# PIC32CM5112GC00048 device description
Architecture: CORTEX-M23; Family: PIC32CM; Series: PIC32CMGC00
Registers are 32-bit, read-write, reset 0x0 unless marked. A register's access mark holds for its fields unless they carry their own. Offsets are from the block's base; [hi:lo] are bit positions; {n}, {i} and the like mark numbered series; 'fields as' and 'values as' point back to an identical list.

## FUSES_CALOTP — Defines FUSES module data
Instances: FUSES_CALOTP 0x0A007000
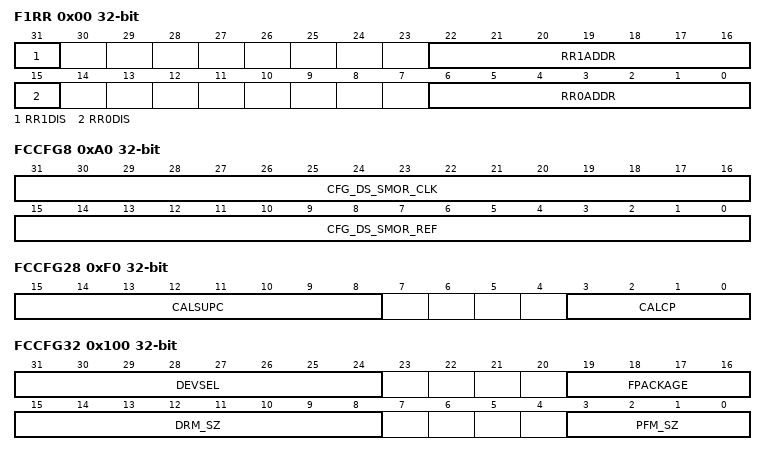
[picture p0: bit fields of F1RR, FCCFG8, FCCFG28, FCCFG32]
0x00 F1RR ro reset not defined — PANEL 0 REDUNDANCY RECORD 1-0 Register
  [31] RR1DIS — Redundancy Record 1 enabled
    0=FCR maps the redundant page 1 into the address defined by RR1ADDR; 1=Redundant page 1 mapping is Disabled
  [22:16] RR1ADDR — Redundancy Replaced Page Address
  [15] RR0DIS — Redundancy Record 0 enabled
    0=FCR maps the redundant page 0 into the address defined by RR0ADDR; 1=Redundant page 0 mapping is Disabled
  [6:0] RR0ADDR — Redundancy Replaced Page Address
0x80 FCCFG0 ro reset not defined — Calibration Configuration 0 Register
  [31:0] CFG_SMOR0 — SMOR configuration bits
0x84 FCCFG1 ro reset not defined — Calibration Configuration 1 Register
  [31:0] CFG_SMOR1 — SMOR configuration bits
0xA0 FCCFG8 ro reset not defined — Calibration Configuration 8 Register
  [31:16] CFG_DS_SMOR_CLK — DSSMOR configuration bits
  [15:0] CFG_DS_SMOR_REF — DSSMOR configuration bits
0xC0 FCCFG16 ro reset not defined — Calibration Configuration 16 Register
  [31:0] CFG_DFLL48M — Comparator configuration bits
0xC4 FCCFG17 ro reset not defined — Calibration Configuration 17 Register
  [15:0] CFG_XTAL_HF — Crystal Oscillator calibration configuration bits
0xE0 FCCFG24 ro reset not defined — Calibration Configuration 24 Register
  [15:0] CFG_CALVREGSW0 — 99 ma VREG Calibration configuration bits
0xEC FCCFG27 ro reset not defined — Calibration Configuration 27 Register
  [31:16] CFG_CALVREGRAM — 50 ma VREG Calibration configuration bits
0xF0 FCCFG28 ro reset not defined — Calibration Configuration 28 Register
  [15:8] CALSUPC — RPMU / SUPC configuration bits
  [3:0] CALCP — Charge Pump Calibration configuration bits for all charge pumps
0xF4 FCCFG29 ro reset not defined — Calibration Configuration 29 Register
  [7:0] CALUSERLDO — User LDO Calibration configuration bits
0x100 FCCFG32 ro reset not defined — DSU Device Configuration 0 Register (DEVID)
  [31:24] DEVSEL — Device Variant Configuration
  [19:16] FPACKAGE — Number of Pins present on the Package
    5=48 pins; 6=64 pins; 8=100 pins
  [15:8] DRM_SZ — Data Ram Memory (DRM) Size on Device
    1=128KB
  [3:0] PFM_SZ — Program Flash Memory (PFM) Size on Device
    6=512KB
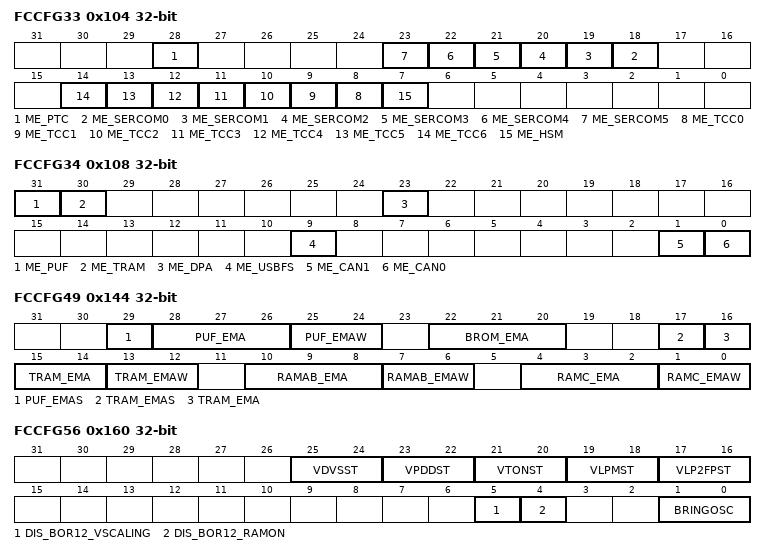
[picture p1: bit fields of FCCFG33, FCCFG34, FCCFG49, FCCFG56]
0x104 FCCFG33 ro reset not defined — DSU Device Configuration 1 Register
  [all] fields
    0=Module is Disabled; 1=Module is Enabled
  [28] ME_PTC — Module enables for Variant configuration
  [n+18] ME_SERCOM{n} (n=0..5) — Module enables for Variant configuration
  [n+8] ME_TCC{n} (n=0..6) — Module enables for Variant configuration
  [7] ME_HSM — Module enables for Variant configuration
0x108 FCCFG34 ro reset not defined — DSU Device Configuration 2 Register
  [31] ME_PUF — Module enables for Variant configuration
    0=Module is Disabled; 1=Module is Enabled
  [30] ME_TRAM — Module enables for Variant configuration
    0=Module is Disabled; 1=Module is Enabled
  [23] ME_DPA — Module enables for Variant configuration
    0=DPA is Disabled; 1=DPA functions in HSM is Operational
  [9] ME_USBFS — Module enables for Variant configuration
    0=Module is Disabled; 1=Module is Enabled
  [1] ME_CAN1 — Module enables for Variant configuration
    0=Module is Disabled; 1=Module is Enabled
  [0] ME_CAN0 — Module enables for Variant configuration
    0=Module is Disabled; 1=Module is Enabled
0x144 FCCFG49 ro reset not defined — Calibration Configuration 49 Register
  [29] PUF_EMAS — Sense Amp Extra Margin Adjust
    0=Sense Amp Pulse Not Extended; 1=Sense Amp Pulse Extended; Default (reset)
  [28:26] PUF_EMA — Cycle and Read Time Extra Margin Adjust
  [25:24] PUF_EMAW — Write Time Extra Margin Adjust
  [22:20] BROM_EMA — Cycle and Read Time Extra Margin Adjust
  [17] TRAM_EMAS — Sense Amp Extra Margin Adjust
    values as PUF_EMAS
  [16:14] TRAM_EMA — Cycle and Read Time Extra Margin Adjust
  [13:12] TRAM_EMAW — Write Time Extra Margin Adjust
  [10:8] RAMAB_EMA — Cycle and Read Time Extra Margin Adjust
  [7:6] RAMAB_EMAW — Write Time Extra Margin Adjust
  [4:2] RAMC_EMA — Cycle and Read Time Extra Margin Adjust
    0=0; 1=1; 2=Slowest Access; 3=3; 4=4; 5=Fastest Access; 6=6; 7=Default (reset)
  [1:0] RAMC_EMAW — Write Time Extra Margin Adjust
    0=Slowest Access; 1=1; 2=2; 3=Fastest Access; Default (reset)
0x160 FCCFG56 ro reset not defined — Calibration Configuration 56 Register
  [25:24] VDVSST — Vreg Down Voltage Scaling Stabilization Time
    0=32us -192 clock cycles based on 6Mhz clock (32US); 1=42us -256 clock cycles based on 6Mhz clock (42US); 2=84us -512 clock cycles based on 6Mhz clock (84US); 3=10us -64 clock cycles based on 6Mhz clock (10US)
  [23:22] VPDDST — Vreg Pull Down Disable Stabilization Time
    0=21us -128 clock cycles based on 6Mhz clock (21US); 1=42us -256 clock cycles based on 6Mhz clock (42US); 2=84us -512 clock cycles based on 6Mhz clock (84US); 3=10.6us -64 clock cycles based on 6Mhz clock (10US)
  [21:20] VTONST — Vreg Turned On Stabilization Time
    0=31us -192 clock cycles based on 6Mhz clock (31US); 1=42us -256 clock cycles based on 6Mhz clock (42US); 2=84us -512 clock cycles based on 6Mhz clock (84US); 3=10.6us -64 clock cycles based on 6Mhz clock (10US)
  [19:18] VLPMST — Vreg LP Mode Stabilization Time
    0=1.3us -8 clock cycles based on 6Mhz clock (1US); 1=2.6us -16 clock cycles based on 6Mhz clock (2US); 2=5us -32 clock cycles based on 6Mhz clock (5US); 3=0.166us -1 clock cycles based on 6Mhz clock (0US)
  [17:16] VLP2FPST — Vreg Low Power to Full Power Stabilization Time
    0=5us -32 clock cycles based on 6Mhz clock (5US); 1=10us -64 clock cycles based on 6Mhz clock (10US); 2=21us -128 clock cycles based on 6Mhz clock (21US); 3=1.3us -8 clock cycles based on 6Mhz clock (1US)
  [5] DIS_BOR12_VSCALING — Disable BOR12 (VREGRAM comparator) when down voltage scaling is on going from 1.2v to 0.8v to workaround VREG undershoot issue
  [4] DIS_BOR12_RAMON — Disable BOR12 (VREGRAM comparator) when RAM are turned ON when leaving sleep mode
  [1:0] BRINGOSC — SUPC Ring-osc depth
    0=Ring oscillator depth is default (DLY0); 1=Ring oscillator depth is default + 1 ORDLY15 (DLY1); 2=Ring oscillator depth is default + 2 ORDLY15 (DLY2); 3=Ring oscillator depth is default + 3 ORDLY15 (DLY3)
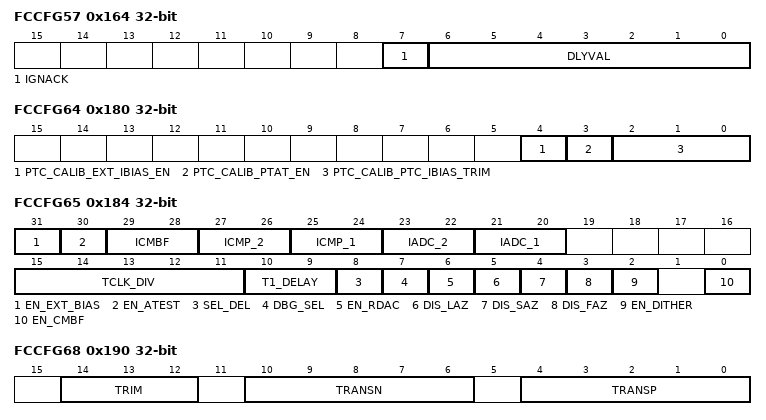
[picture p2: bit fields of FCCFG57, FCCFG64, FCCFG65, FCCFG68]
0x164 FCCFG57 ro reset not defined — Calibration Configuration 57 Register
  [7] IGNACK — Ignore Acknowledge
    0=Power Switch acknowledge signal is taken into account when entering/exiting retention mode. According to the DLYVAL field, a supplementary delay is also added (from 0 to 127 digital ring oscillator period); 1=Power Switch acknowledge signal is ignored when entering/exiting retention mode, and is replaced by a overflow counter signal clocked on internal digital ring oscillator. The overflow counter is programmable by using the DLYVAL field
  [6:0] DLYVAL — Delay Value
0x168 FCCFG58 ro reset not defined — Calibration Configuration 58 Register
  [1:0] BRINGOSC — Backup Ring Oscillator Size Depth
    0=Ring Oscillator depth is default (DLY0); 1=Ring Oscillator depth is default + 1 ORDLY15 (DLY1); 2=Ring Oscillator depth is default + 2 ORDLU15 (DLY2); 3=Ring Oscillator depth is default + 3 ORDLY15 (DLY3)
0x16C FCCFG59 ro reset not defined — Calibration Configuration 59 Register
  [0] IDAU_EN — IDAU Enabled
    0=GC device. All IDAU regions exempt. The boot code will initialize the IDAU, H2PB and PAC as described in Section 2.9.2; 1=IDAU regions enabled. The boot code will initialize the IDAU, H2PB and PAC to the values set by customer and referred to in USERCFG as described in Section 2.9.3
0x170 FCCFG60 ro reset not defined — Calibration Configuration 60 Register
  [31:0] PUFRAMDNTIME — PUF RAM Power Down Delay Time
0x174 FCCFG61 ro reset not defined — Calibration Configuration 61 Register
  [31:0] PUFRAMUPTIME — PUF RAM Power Up Delay Time
0x180 FCCFG64 ro reset not defined — Calibration Configuration 64 Register
  [4] PTC_CALIB_EXT_IBIAS_EN — Enable External Bias
  [3] PTC_CALIB_PTAT_EN — Enable PTAT current
  [2:0] PTC_CALIB_PTC_IBIAS_TRIM — PTC IBIAS TRIM
0x184 FCCFG65 ro reset not defined — Calibration Configuration 65 Register
  [31] EN_EXT_BIAS — Internal switched capacitor bias current allows to make the bias current proportional to conversion frequency.
  [30] EN_ATEST — Enable analog test signals
  [29:28] ICMBF — Controls the bias current for Common mode buffer amplifier (CMBF)
  [27:26] ICMP_2 — Controls the bias current for 2 stage of the comparator. This will control the resolution needed by comparator. More current means less time but at expense of gain.
  [25:24] ICMP_1 — Controls the bias current for 1 stage of the comparator. This will control the resolution needed by comparator. More current means less time but at expense of gain.
  [23:22] IADC_2 — Controls the current consumption for of the whole ADC.
  [21:20] IADC_1 — Controls the current consumption for of the whole ADC
  [15:11] TCLK_DIV — Programmable divider for adc_clk_div. The division ratio is 256, 128, 64,32, and 16 going from MSB to LSB.
  [10:9] T1_DELAY — Programmable delay, selects the delay between regen and latch
  [8] SEL_DEL — Select Value to comp_out
  [7] DBG_SEL — Enable Test Output
  [6] EN_RDAC — RDAC Duty Cycle
  [5] DIS_LAZ — Current Auto Zeroing
  [4] DIS_SAZ — Second Auto Zeroing
  [3] DIS_FAZ — First Auto Zeroing
  [2] EN_DITHER — Enable Dithering
  [0] EN_CMBF — Enable Common Mode Power Cycling
0x188 FCCFG66 ro reset not defined — Calibration Configuration 66 Register
  [3:0] AC_CONFIG — Comparator 0 Calibration Configuration bits.'
0x190 FCCFG68 ro reset not defined — Calibration Configuration 68 Register
  [14:12] TRIM — USB PAD Rise/Fall Configuration bits.'
  [10:6] TRANSN — USB PAD N Driver Configuration bits.'
  [4:0] TRANSP — USB PAD P Driver Configuration bits.'
